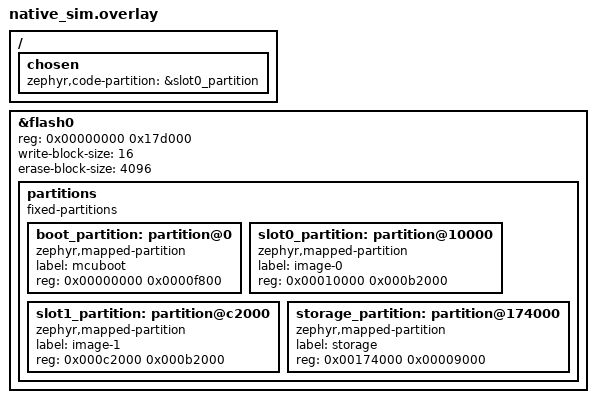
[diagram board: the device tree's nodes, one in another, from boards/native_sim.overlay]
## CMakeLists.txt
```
# Copyright (c) Meta Platforms, Inc. and affiliates.
#
# Licensed under the Apache License, Version 2.0 (the "License");
# you may not use this file except in compliance with the License.
# You may obtain a copy of the License at
#
#     http://www.apache.org/licenses/LICENSE-2.0
#
# Unless required by applicable law or agreed to in writing, software
# distributed under the License is distributed on an "AS IS" BASIS,
# WITHOUT WARRANTIES OR CONDITIONS OF ANY KIND, either express or implied.
# See the License for the specific language governing permissions and
# limitations under the License.

# The XIAO's firmware-update path on native_sim, for the Muse apps' mcumgr
# clients (README.md): Zephyr's MCUmgr (img_mgmt, os_mgmt, the BLE
# transport's reassembly) with the XIAO's settings, src/mg_ota.c as built
# for the board, and MCUboot's own loader (swap using move) run on the
# simulated RRAM at every start, behind a UDP "fake GATT" link.

cmake_minimum_required(VERSION 3.20.0)

find_package(Zephyr REQUIRED HINTS $ENV{ZEPHYR_BASE})
project(mg_smp_link)

set(MG_SRC ${CMAKE_CURRENT_SOURCE_DIR}/../../src)
set(MG_PROTOCOLS ${CMAKE_CURRENT_SOURCE_DIR}/../../../protocols)
set(MCUBOOT ${ZEPHYR_MCUBOOT_MODULE_DIR})

target_include_directories(app PRIVATE ${MG_SRC} src ${MG_PROTOCOLS}
  ${ZEPHYR_BASE}/subsys/mgmt/mcumgr/transport/include)
target_sources(app PRIVATE src/main.c src/link.c src/stubs.c src/boot_sim.c ${MG_SRC}/mg_ota.c)

# As on the XIAO: Zephyr's smp.c replaced by the board's copy
# (buffers and work queue allocated while SMP is in use), the image writer
# from the wrap in mg_smp_mem.c.
set(MG_SDK_SRC ${CMAKE_CURRENT_SOURCE_DIR}/../../src)
target_sources(app PRIVATE ${MG_SDK_SRC}/mg_smp_mem.c)
zephyr_link_libraries(-Wl,--wrap=img_mgmt_write_image_data)
get_target_property(mg_mcumgr_srcs mcumgr_transport SOURCES)
list(FILTER mg_mcumgr_srcs EXCLUDE REGEX "(^|/subsys/mgmt/mcumgr/transport/)src/smp\\.c$")
set_property(TARGET mcumgr_transport PROPERTY SOURCES ${mg_mcumgr_srcs})
target_sources(mcumgr_transport PRIVATE ${MG_SDK_SRC}/zephyr/smp.c)
target_link_libraries(app PRIVATE MCUBOOT_BOOTUTIL)
# As on the board (CMakeLists.txt): img_mgmt's state write goes through
# mg_ota.c's boot_set_next(). And an SMP reset ends the process with status
# 77 instead of re-executing it, so run.py can restart it (src/main.c).
zephyr_link_libraries(-Wl,--wrap=boot_set_next -Wl,--wrap=sys_arch_reboot)
# src/link.c feeds writes to the reassembly as smp_bt does (expected, then
# collect): through mg_ota.c's gap check, as on the board.
zephyr_link_libraries(-Wl,--wrap=smp_reassembly_expected -Wl,--wrap=smp_reassembly_collect)

# MCUboot's loader, configured like the XIAO's (mcuboot/mcuboot_config,
# found before MCUboot's own Zephyr config).
target_include_directories(app BEFORE PRIVATE ${CMAKE_CURRENT_SOURCE_DIR}/mcuboot)
target_include_directories(app PRIVATE
  ${MCUBOOT}/boot/bootutil/include ${MCUBOOT}/boot/bootutil/src
  ${MCUBOOT}/boot/zephyr/include ${MCUBOOT}/ext/tinycrypt/lib/include)
target_sources(app PRIVATE
  ${MCUBOOT}/boot/bootutil/src/loader.c
  ${MCUBOOT}/boot/bootutil/src/bootutil_loader.c
  ${MCUBOOT}/boot/bootutil/src/bootutil_misc.c
  ${MCUBOOT}/boot/bootutil/src/bootutil_area.c
  ${MCUBOOT}/boot/bootutil/src/swap_misc.c
  ${MCUBOOT}/boot/bootutil/src/swap_move.c
  ${MCUBOOT}/boot/bootutil/src/swap_scratch.c
  ${MCUBOOT}/boot/bootutil/src/image_validate.c
  ${MCUBOOT}/boot/bootutil/src/bootutil_img_hash.c
  ${MCUBOOT}/boot/bootutil/src/tlv.c
  ${MCUBOOT}/boot/bootutil/src/fault_injection_hardening.c
  ${MCUBOOT}/boot/zephyr/flash_map_extended.c
  ${MCUBOOT}/ext/tinycrypt/lib/source/sha256.c
  ${MCUBOOT}/ext/tinycrypt/lib/source/utils.c
)
# The release rule at run time (--release), for the update prompt rows.
target_compile_definitions(app PRIVATE MG_SMP_LINK_SIM)
```

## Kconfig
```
# Copyright (c) Meta Platforms, Inc. and affiliates.
#
# Licensed under the Apache License, Version 2.0 (the "License");
# you may not use this file except in compliance with the License.
# You may obtain a copy of the License at
#
#     http://www.apache.org/licenses/LICENSE-2.0
#
# Unless required by applicable law or agreed to in writing, software
# distributed under the License is distributed on an "AS IS" BASIS,
# WITHOUT WARRANTIES OR CONDITIONS OF ANY KIND, either express or implied.
# See the License for the specific language governing permissions and
# limitations under the License.

mainmenu "Muse Gadget SMP link harness"

# The few Muse Gadget options src/mg_ota.c reads. ../../Kconfig.mg is the
# source of truth (defaults and ranges copied from it; change both
# together): there they depend on MG_DFU, which needs BOOTLOADER_MCUBOOT,
# which native_sim doesn't build.
config MG_DFU_RESET_DISCONNECT_MS
	int "Delay from an SMP reset's answer to dropping the link (ms)"
	default 100
	range 20 400

config MG_SMP_SESSION_IDLE_MS
	int "Idle time after which SMP's work queue is freed (ms)"
	default 2000

config MG_SMP_RX_GAP_MS
	int "Gap after which a partly received SMP request is dropped (ms)"
	default 2000
	range 0 10000

config MG_SIM_LINK
	bool
	default y
	select MCUMGR_TRANSPORT_REASSEMBLY
	help
	  src/link.c reassembles SMP requests from ATT-sized writes, as the
	  BLE transport does (CONFIG_MCUMGR_TRANSPORT_BT_REASSEMBLY).

config MG_AUTOMATION
	bool "An automation build (the bench board's)"
	default y
	help
	  mg_ota.c's update window rule for a gadget that isn't set up applies
	  to release builds only, and this suite updates unset gadgets as CI
	  does.

config MG_BENCH_NO_CONFIRM
	bool "Never confirm a new image (revert test)"

module = MG
module-str = Muse Gadget
source "subsys/logging/Kconfig.template.log_config"

source "Kconfig.zephyr"
```

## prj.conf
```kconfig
# Copyright (c) Meta Platforms, Inc. and affiliates.
#
# Licensed under the Apache License, Version 2.0 (the "License");
# you may not use this file except in compliance with the License.
# You may obtain a copy of the License at
#
#     http://www.apache.org/licenses/LICENSE-2.0
#
# Unless required by applicable law or agreed to in writing, software
# distributed under the License is distributed on an "AS IS" BASIS,
# WITHOUT WARRANTIES OR CONDITIONS OF ANY KIND, either express or implied.
# See the License for the specific language governing permissions and
# limitations under the License.

# MCUmgr as the XIAO builds it (boards/xiao_nrf54l15_nrf54l15_cpuapp.conf;
# run.py checks the shared lines haven't drifted), minus Bluetooth: the
# link is UDP (src/link.c) feeding the same reassembly.
CONFIG_MCUMGR=y
CONFIG_NET_BUF=y
CONFIG_ZCBOR=y
CONFIG_CRC=y
CONFIG_FLASH=y
CONFIG_FLASH_MAP=y
CONFIG_STREAM_FLASH=y
CONFIG_IMG_MANAGER=y
CONFIG_MCUBOOT_IMG_MANAGER=y
CONFIG_MCUMGR_GRP_IMG=y
CONFIG_MCUMGR_GRP_IMG_STATUS_HOOKS=y
CONFIG_MCUMGR_GRP_IMG_UPLOAD_CHECK_HOOK=y
CONFIG_MCUMGR_GRP_OS=y
CONFIG_MCUMGR_GRP_OS_ECHO=y
CONFIG_MCUMGR_GRP_OS_INFO=y
CONFIG_MCUMGR_MGMT_NOTIFICATION_HOOKS=y
CONFIG_MCUMGR_TRANSPORT_NETBUF_SIZE=512
CONFIG_MCUMGR_TRANSPORT_NETBUF_COUNT=4
CONFIG_MCUMGR_GRP_OS_MCUMGR_PARAMS=y
CONFIG_IMG_BLOCK_BUF_SIZE=4096
CONFIG_IMG_ERASE_PROGRESSIVELY=y
CONFIG_MCUMGR_TRANSPORT_WORKQUEUE_STACK_SIZE=4096
CONFIG_MCUMGR_GRP_OS_RESET_MS=500
# What CONFIG_MG_DFU selects on the board.
CONFIG_MCUMGR_SMP_COMMAND_STATUS_HOOKS=y
CONFIG_MCUMGR_GRP_OS_RESET_HOOK=y
CONFIG_REBOOT=y
# The XIAO's MCUboot writes 16-byte RRAM words (CONFIG_MCUBOOT_BOOT_MAX_ALIGN
# from sysbuild); the loader here uses the same (mcuboot/mcuboot_config).
CONFIG_MCUBOOT_BOOT_MAX_ALIGN=16
# img_mgmt finds the running slot from the chosen code partition (slot0).
CONFIG_USE_DT_CODE_PARTITION=y
# RRAM: no erase before a write (as tests/unit's rram and slot1 builds).
CONFIG_FLASH_SIMULATOR=y
CONFIG_FLASH_SIMULATOR_EXPLICIT_ERASE=n
CONFIG_FLASH_SIMULATOR_UNALIGNED_READ=y
CONFIG_FLASH_SIMULATOR_DOUBLE_WRITES=y

# The UDP link: host sockets (native simulator offloaded sockets).
CONFIG_NETWORKING=y
CONFIG_NET_DRIVERS=y
CONFIG_NET_SOCKETS=y
CONFIG_NET_SOCKETS_OFFLOAD=y
CONFIG_NET_NATIVE_OFFLOADED_SOCKETS=y
CONFIG_NET_IPV6=n
CONFIG_NET_IPV4=y
CONFIG_ETH_NATIVE_TAP=n

CONFIG_MAIN_STACK_SIZE=8192
CONFIG_SYSTEM_WORKQUEUE_STACK_SIZE=4096
CONFIG_LOG=y
CONFIG_LOG_MODE_IMMEDIATE=y
CONFIG_MG_LOG_LEVEL_INF=y
CONFIG_IMG_MANAGER_LOG_LEVEL_INF=y
CONFIG_MCUMGR_GRP_IMG_LOG_LEVEL_INF=y

# SMP's memory from the C library's arena (all free RAM on the XIAO).
# Zephyr's own malloc (sys_heap over a fixed arena) as on the board, not the
# host's: native_sim links the host C library by default, whose malloc never
# runs out, and an arena that can't run out proves nothing about sharing it.
CONFIG_PICOLIBC=y
CONFIG_COMMON_LIBC_MALLOC=y
CONFIG_COMMON_LIBC_MALLOC_ARENA_SIZE=65536
# Asserts on: Zephyr's own checks on the buffers the smp.c copy makes.
CONFIG_ASSERT=y

# Room after the transport's user data for each request's source connection
# (src/zephyr/smp.c, change 3).
CONFIG_MCUMGR_TRANSPORT_NETBUF_USER_DATA_SIZE=16
```

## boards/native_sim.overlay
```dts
/*
 * Copyright (c) Meta Platforms, Inc. and affiliates.
 *
 * Licensed under the Apache License, Version 2.0 (the "License");
 * you may not use this file except in compliance with the License.
 * You may obtain a copy of the License at
 *
 *     http://www.apache.org/licenses/LICENSE-2.0
 *
 * Unless required by applicable law or agreed to in writing, software
 * distributed under the License is distributed on an "AS IS" BASIS,
 * WITHOUT WARRANTIES OR CONDITIONS OF ANY KIND, either express or implied.
 * See the License for the specific language governing permissions and
 * limitations under the License.
 */

/* The XIAO nRF54L15's RRAM map (nrf54l15_cpuapp_partition.dtsi): 1524 KB,
 * 16-byte words, MCUboot's slots at the board's offsets. */

/delete-node/ &boot_partition;
/delete-node/ &slot0_partition;
/delete-node/ &slot1_partition;
/delete-node/ &scratch_partition;
/delete-node/ &storage_partition;

&flash0 {
	reg = <0x00000000 0x17d000>;
	write-block-size = <16>;
	erase-block-size = <4096>;

	partitions {
		compatible = "fixed-partitions";
		#address-cells = <1>;
		#size-cells = <1>;

		boot_partition: partition@0 {
			compatible = "zephyr,mapped-partition";
			label = "mcuboot";
			reg = <0x00000000 0x0000f800>;
		};
		slot0_partition: partition@10000 {
			compatible = "zephyr,mapped-partition";
			label = "image-0";
			reg = <0x00010000 0x000b2000>;
		};
		slot1_partition: partition@c2000 {
			compatible = "zephyr,mapped-partition";
			label = "image-1";
			reg = <0x000c2000 0x000b2000>;
		};
		storage_partition: partition@174000 {
			compatible = "zephyr,mapped-partition";
			label = "storage";
			reg = <0x00174000 0x00009000>;
		};
	};
};

/ {
	chosen {
		zephyr,code-partition = &slot0_partition;
	};
};
```

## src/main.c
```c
/*
 * Copyright (c) Meta Platforms, Inc. and affiliates.
 *
 * Licensed under the Apache License, Version 2.0 (the "License");
 * you may not use this file except in compliance with the License.
 * You may obtain a copy of the License at
 *
 *     http://www.apache.org/licenses/LICENSE-2.0
 *
 * Unless required by applicable law or agreed to in writing, software
 * distributed under the License is distributed on an "AS IS" BASIS,
 * WITHOUT WARRANTIES OR CONDITIONS OF ANY KIND, either express or implied.
 * See the License for the specific language governing permissions and
 * limitations under the License.
 */

/*
 * Boot like the XIAO: MCUboot (boot_sim.c), then the app's update path
 * (mg_ota_init(), the SMP service on the link), healthy
 * --healthy-ms after it is up (CONFIG_MG_HEALTHY_AFTER_MS on the board,
 * 30 s). --crash-ms restarts before that, as a watchdog would (a test image
 * that never gets healthy). An SMP reset (or that crash) ends the process
 * with status 77; run.py starts it again, which is the next boot.
 */

#include <stdlib.h>

#include <zephyr/kernel.h>
#include <zephyr/sys/printk.h>

#include "cmdline.h"
#include "posix_board_if.h"
#include "soc.h"

#include "mg_ota.h"
#include "sim.h"
#include "mg_zephyr_version.h"

MG_ZEPHYR_WRAPS_CHECK(); /* __wrap_sys_arch_reboot */

#define EXIT_REBOOT 77

static uint32_t opt_port = 47000;
static uint32_t opt_healthy_ms = 30000;
static uint32_t opt_crash_ms;
static bool opt_never_healthy;
static bool opt_ready_at_healthy;
static uint32_t opt_hold_kb;
bool sim_healthy;
uint32_t sim_boot;

static void add_options(void)
{
	static struct args_struct_t opts[] = {
		{.option = "port", .name = "port", .type = 'u', .dest = &opt_port,
		 .descript = "UDP port of the fake GATT link (47000)"},
		{.option = "healthy-ms", .name = "ms", .type = 'u', .dest = &opt_healthy_ms,
		 .descript = "healthy this long after start (30000, the XIAO's)"},
		{.option = "crash-ms", .name = "ms", .type = 'u', .dest = &opt_crash_ms,
		 .descript = "restart this long after start, before healthy (a watchdog reset)"},
		{.is_switch = true, .option = "never-healthy", .type = 'b',
		 .dest = &opt_never_healthy, .descript = "never reach healthy"},
		{.is_switch = true, .option = "safe", .type = 'b', .dest = &sim_safe_mode,
		 .descript = "run in SAFE mode (from failed boots)"},
		{.is_switch = true, .option = "safe-button", .type = 'b', .dest = &sim_safe_button,
		 .descript = "with --safe: SAFE mode asked with the button"},
		{.is_switch = true, .option = "set-up", .type = 'b', .dest = &sim_set_up,
		 .descript = "set up (a proof key stored; on --release the update gate asks the "
			     "same either way)"},
		{.is_switch = true, .option = "release", .type = 'b', .dest = &sim_release,
		 .descript = "a release build's update rule (unproven writes ask for the press)"},
		{.is_switch = true, .option = "proven", .type = 'b', .dest = &sim_proven,
		 .descript = "the client passed the token proof"},
		{.option = "boot", .name = "n", .type = 'u', .dest = &sim_boot,
		 .descript = "this boot's number (run.py counts them)"},
		{.option = "hold-kb", .name = "kb", .type = 'u', .dest = &opt_hold_kb,
		 .descript = "take this much of the malloc arena at start and keep it (the "
			     "device session's block, which shares the arena with SMP)"},
		{.is_switch = true, .option = "ready-at-healthy", .type = 'b',
		 .dest = &opt_ready_at_healthy,
		 .descript = "answer connects with ready only once healthy"},
		ARG_TABLE_ENDMARKER,
	};

	native_add_command_line_opts(opts);
}

NATIVE_TASK(add_options, PRE_BOOT_1, 10);

/* sys_reboot() (the SMP reset, a crash) ends here: hand back to run.py. */
void __wrap_sys_arch_reboot(int type)
{
	printk("SIM: reboot (%d)\n", type);
	posix_exit(EXIT_REBOOT);
}

static void healthy_fn(struct k_work *w)
{
	ARG_UNUSED(w);
	printk("SIM: boot healthy\n");
	sim_healthy = true;
	if (opt_ready_at_healthy) {
		link_set_ready(true);
	}
	mg_ota_healthy();
}

static K_WORK_DELAYABLE_DEFINE(healthy_work, healthy_fn);

static void crash_fn(struct k_work *w)
{
	ARG_UNUSED(w);
	printk("SIM: crash before healthy (watchdog)\n");
	posix_exit(EXIT_REBOOT);
}

static K_WORK_DELAYABLE_DEFINE(crash_work, crash_fn);

/* The native simulator sets every 'u' option it wasn't given to UINT32_MAX. */
static void option_defaults(void)
{
	if (opt_port == UINT32_MAX) {
		opt_port = 47000;
	}
	if (opt_healthy_ms == UINT32_MAX) {
		opt_healthy_ms = 30000;
	}
	if (opt_crash_ms == UINT32_MAX) {
		opt_crash_ms = 0;
	}
	if (sim_boot == UINT32_MAX) {
		sim_boot = 0;
	}
	if (opt_hold_kb == UINT32_MAX) {
		opt_hold_kb = 0;
	}
}

int main(void)
{
	option_defaults();
	sim_proven_at_connect = sim_proven;
	if (boot_sim_run() != 0) {
		posix_exit(2);
	}
	sim_app_wq_start();
	if (opt_hold_kb) {
		/* As the device session's block (from a hello to the connection's
		 * end): taken before SMP's, from the same arena, never given back. */
		void *held = malloc(opt_hold_kb * 1024U);

		printk("SIM: holding %u KB of the malloc arena%s\n", opt_hold_kb,
		       held ? "" : ": FAILED");
		if (held == NULL) {
			posix_exit(4);
		}
	}
	mg_ota_init();
	if (link_start((uint16_t)opt_port) != 0) {
		posix_exit(3);
	}
	link_set_ready(!opt_ready_at_healthy);
	printk("SIM: up (healthy in %u ms%s%s)\n", opt_healthy_ms,
	       opt_never_healthy ? ", never" : "", sim_safe_mode ? ", SAFE mode" : "");
	if (opt_crash_ms) {
		k_work_reschedule(&crash_work, K_MSEC(opt_crash_ms));
	}
	if (!opt_never_healthy && !opt_crash_ms) {
		k_work_reschedule(&healthy_work, K_MSEC(opt_healthy_ms));
	}
	return 0;
}
```

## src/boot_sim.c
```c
/*
 * Copyright (c) Meta Platforms, Inc. and affiliates.
 *
 * Licensed under the Apache License, Version 2.0 (the "License");
 * you may not use this file except in compliance with the License.
 * You may obtain a copy of the License at
 *
 *     http://www.apache.org/licenses/LICENSE-2.0
 *
 * Unless required by applicable law or agreed to in writing, software
 * distributed under the License is distributed on an "AS IS" BASIS,
 * WITHOUT WARRANTIES OR CONDITIONS OF ANY KIND, either express or implied.
 * See the License for the specific language governing permissions and
 * limitations under the License.
 */

/*
 * The reset path: MCUboot's own loader (bootutil, configured in
 * ../mcuboot/mcuboot_config) runs on the simulated flash before the app
 * starts, so a test, a confirm, a revert and a refused image go through
 * MCUboot's real swap-using-move code. What the app reports comes from the
 * flash, as on the board.
 */

#include <zephyr/logging/log.h>
#include <zephyr/sys/printk.h>

#include <bootutil/bootutil.h>
#include <bootutil/fault_injection_hardening.h>
#include <bootutil/image.h>

#include "sim.h"

LOG_MODULE_REGISTER(mcuboot, LOG_LEVEL_INF);

int boot_sim_run(void)
{
	struct boot_rsp rsp;
	FIH_DECLARE(fih_rc, FIH_FAILURE);

	FIH_CALL(boot_go, fih_rc, &rsp);
	if (FIH_NOT_EQ(fih_rc, FIH_SUCCESS)) {
		printk("SIM: mcuboot: no bootable image\n");
		return -1;
	}
	printk("SIM: mcuboot: booting %u.%u.%u+%u\n", rsp.br_hdr->ih_ver.iv_major,
	       rsp.br_hdr->ih_ver.iv_minor, rsp.br_hdr->ih_ver.iv_revision,
	       rsp.br_hdr->ih_ver.iv_build_num);
	return 0;
}
```

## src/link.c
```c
/*
 * Copyright (c) Meta Platforms, Inc. and affiliates.
 *
 * Licensed under the Apache License, Version 2.0 (the "License");
 * you may not use this file except in compliance with the License.
 * You may obtain a copy of the License at
 *
 *     http://www.apache.org/licenses/LICENSE-2.0
 *
 * Unless required by applicable law or agreed to in writing, software
 * distributed under the License is distributed on an "AS IS" BASIS,
 * WITHOUT WARRANTIES OR CONDITIONS OF ANY KIND, either express or implied.
 * See the License for the specific language governing permissions and
 * limitations under the License.
 */

/*
 * The "fake GATT" link (the one
 * esp32/components/muse_gadget_ble/smp/conformance/smplink.py speaks): UDP
 * datagrams of one type byte and a value. Data
 * from the client is one ATT write without response (at most MTU - 3
 * bytes); data to it is one notification. The SMP side copies smp_bt.c:
 * every write goes through Zephyr's SMP reassembly into the board's
 * buffers, a response is cut into MTU - 3 notifications, and a response to
 * a request from an earlier connection is dropped. A disconnect drops a
 * partly received request, as smp_bt's CCC cleanup does for a central that
 * subscribed; a disconnect whose value byte is 1 is a central that never
 * subscribed, and keeps it, as smp_bt does (GATT's cleanup skips a CCC that
 * was never enabled), so the board's own reassembly wraps (src/mg_ota.c)
 * must drop it before the next connection's writes complete it.
 */

#include <errno.h>
#include <string.h>

#include <stdio.h>

#include <zephyr/dfu/mcuboot.h>
#include <zephyr/kernel.h>
#include <zephyr/mgmt/mcumgr/mgmt/mgmt_defines.h>
#include <zephyr/storage/flash_map.h>
#include <zephyr/mgmt/mcumgr/smp/smp.h>
#include <zephyr/mgmt/mcumgr/transport/smp.h>
#include <zephyr/net/socket.h>
#include <zephyr/sys/atomic.h>
#include <zephyr/sys/printk.h>

#include <mgmt/mcumgr/transport/smp_reassembly.h>

#include "mg_ota.h"
#include "sim.h"

/* The largest attribute value ATT allows (Core spec Vol 3 Part F 3.2.9). */
#define ATT_MAX_VALUE 512U

enum {
	T_DATA = 0x00,
	T_CONNECT = 0x01,
	T_DISCONNECT = 0x02,
	T_READY = 0x04,
	T_DROP_NEXT = 0x05,
	T_STATUS = 0x07,
	T_AUTH = 0x09, /* this connection proven (1) or not (0): the update gate */
	/* This app's own, outside the link's shared range: a setup committed (an
	 * ownership change), as mg_setup_store_commit_device_key() reports it. */
	T_SETUP_COMMITTED = 0x40,
	T_PRESS = 0x41, /* a real press of the talk button (the update prompt) */
	T_INJECTED = 0x42, /* an injected press (a console word): never a confirm on release */
	/* Forget (the token proof's clear, the sealed clear, the reset hold):
	 * the link's proof ends, then the store is erased (mg_setup_factory_reset()). */
	T_FORGET = 0x43,
};

/* src/mg_ota.c: the setup store erased (mg_setup_store_erase() reports it). */
void mg_setup_store_erased(void);

#define MAX_DGRAM 600 /* MTU 517 + the type byte, with room */

struct link_ud {
	uint32_t id; /* the connection the request came on */
};
BUILD_ASSERT(sizeof(struct link_ud) <= CONFIG_MCUMGR_TRANSPORT_NETBUF_USER_DATA_SIZE);

static int sock = -1;
static struct net_sockaddr_in peer;
static bool have_peer;
static uint16_t att_mtu = 23;
static atomic_t conn_id;    /* 0: no client */
static uint32_t next_id = 1;
static bool gatt_ready;
static bool held;
static int drop_next;
static bool kept_partial; /* left by a central that never subscribed */
static struct smp_transport smpt;
static K_MUTEX_DEFINE(tx_lock);

static void send_dgram(uint8_t type, const uint8_t *v, size_t n)
{
	uint8_t d[MAX_DGRAM];

	if (!have_peer || sock < 0 || n + 1 > sizeof(d)) {
		return;
	}
	d[0] = type;
	if (n) {
		memcpy(&d[1], v, n);
	}
	(void)zsock_sendto(sock, d, n + 1, 0, (struct net_sockaddr *)&peer, sizeof(peer));
}

static uint16_t link_get_mtu(const struct net_buf *nb)
{
	ARG_UNUSED(nb);
	return atomic_get(&conn_id) ? att_mtu - 3 : 0;
}

static int link_tx(struct net_buf *nb)
{
	const struct link_ud *ud = net_buf_user_data(nb);
	int rc = MGMT_ERR_EOK;
	uint32_t id = (uint32_t)atomic_get(&conn_id);

	if (id == 0 || ud->id != id) {
		/* The client that asked is gone (smp_bt drops these too). */
		rc = MGMT_ERR_ENOENT;
	} else {
		uint16_t chunk = att_mtu - 3;

		k_mutex_lock(&tx_lock, K_FOREVER);
		for (uint16_t off = 0; off < nb->len; off += chunk) {
			send_dgram(T_DATA, nb->data + off, MIN(chunk, nb->len - off));
		}
		k_mutex_unlock(&tx_lock);
	}
	smp_packet_free(nb);
	return rc;
}

static int link_ud_copy(struct net_buf *dst, const struct net_buf *src)
{
	memcpy(net_buf_user_data(dst), net_buf_user_data(src), sizeof(struct link_ud));
	return MGMT_ERR_EOK;
}

static void link_ud_free(void *ud)
{
	ARG_UNUSED(ud);
}

static void drop_partial(void)
{
	if (smp_reassembly_expected(&smpt) >= 0) {
		(void)smp_reassembly_drop(&smpt);
	}
}

static void on_data(const uint8_t *v, size_t n)
{
	uint32_t id = (uint32_t)atomic_get(&conn_id);

	if (id == 0 || n == 0) {
		return;
	}
	kept_partial = false; /* the board's wraps decide from here */
	if (drop_next > 0) {
		drop_next--;
		printk("SIM: link: dropped a write (%u B) as asked\n", (unsigned int)n);
		return;
	}
	if (n > att_mtu - 3U || n > ATT_MAX_VALUE) {
		/* Android refuses a write over 512 B whatever the MTU (and ATT
		 * caps an attribute value there): count it as a failure. */
		printk("SIM: link: write of %u B is over MTU - 3 (%u) or %u: refused\n",
		       (unsigned int)n, att_mtu - 3U, ATT_MAX_VALUE);
		return;
	}
	bool started = smp_reassembly_expected(&smpt) >= 0;
	int ret = smp_reassembly_collect(&smpt, v, (uint16_t)n);

	if (ret < 0) {
		printk("SIM: link: reassembly refused a write (%d): request dropped\n", ret);
		drop_partial();
		return;
	}
	if (!started) {
		struct link_ud *ud = smp_reassembly_get_ud(&smpt);

		if (ud) {
			ud->id = id;
		}
	}
	if (ret == 0) {
		(void)smp_reassembly_complete(&smpt, false);
	}
}

static bool slot_version(uint8_t area, char *out, size_t len)
{
	struct mcuboot_img_header h;

	if (boot_read_bank_header(area, &h, sizeof(h)) != 0) {
		snprintf(out, len, "none");
		return false;
	}
	snprintf(out, len, "%u.%u.%u+%u", h.h.v1.sem_ver.major, h.h.v1.sem_ver.minor,
		 h.h.v1.sem_ver.revision, h.h.v1.sem_ver.build_num);
	return true;
}

/* 0x07: what the running gadget says about itself, for checks. */
static void send_status(void)
{
	static const char *const swaps[] = {"?", "none", "test", "perm", "revert", "fail"};
	char running[24], staged[24], j[256];
	int swap = mcuboot_swap_type();
	bool has_staged = slot_version(FIXED_PARTITION_ID(slot1_partition), staged, sizeof(staged));

	(void)slot_version(FIXED_PARTITION_ID(slot0_partition), running, sizeof(running));
	int n = snprintf(j, sizeof(j),
			 "{\"running\":\"%s\",\"confirmed\":%s,\"swap\":\"%s\",\"pending\":%s,"
			 "\"staged\":%s,\"staged_version\":\"%s\",\"healthy\":%s,\"boot\":%u,"
			 "\"safe\":%s,\"smp_blocks\":%d}",
			 running, boot_is_img_confirmed() ? "true" : "false",
			 swap >= 0 && swap < (int)ARRAY_SIZE(swaps) ? swaps[swap] : "?",
			 swap != BOOT_SWAP_TYPE_NONE ? "true" : "false", has_staged ? "true" : "false",
			 staged, sim_healthy ? "true" : "false", sim_boot, sim_safe_mode ? "true" : "false",
			 mg_smp_mem_blocks());

	send_dgram(T_STATUS, (const uint8_t *)j, (size_t)MIN(n, (int)sizeof(j) - 1));
}

static void rx_fn(void *a, void *b, void *c)
{
	uint8_t d[MAX_DGRAM];

	ARG_UNUSED(a);
	ARG_UNUSED(b);
	ARG_UNUSED(c);
	for (;;) {
		struct net_sockaddr_in from;
		net_socklen_t fl = sizeof(from);
		ssize_t n = zsock_recvfrom(sock, d, sizeof(d), 0, (struct net_sockaddr *)&from, &fl);

		if (n < 1) {
			k_sleep(K_MSEC(10));
			continue;
		}
		if (have_peer && (from.sin_port != peer.sin_port ||
				  from.sin_addr.s_addr != peer.sin_addr.s_addr) &&
		    d[0] != T_CONNECT) {
			continue; /* only the client that connected speaks for the link */
		}
		peer = from;
		have_peer = true;
		switch (d[0]) {
		case T_DATA:
			on_data(&d[1], (size_t)n - 1);
			break;
		case T_CONNECT:
			if (held) {
				break; /* restarting: no new link */
			}
			att_mtu = n >= 3 ? (uint16_t)(d[1] | (d[2] << 8)) : 23;
			att_mtu = CLAMP(att_mtu, 23, MAX_DGRAM - 1);
			if (!kept_partial) {
				drop_partial();
			}
			drop_next = 0;
			atomic_set(&conn_id, (atomic_val_t)next_id++);
			sim_proven = sim_proven_at_connect; /* --proven: every connection */
			printk("SIM: link: connected (ATT MTU %u)\n", att_mtu);
			/* A working link: as the gadget's own MTU exchange answered
			 * (mg_ble.c), so an updated image may keep itself. */
			mg_ota_link_proven();
			if (gatt_ready) {
				send_dgram(T_READY, NULL, 0);
			}
			break;
		case T_DISCONNECT:
			if (atomic_get(&conn_id)) {
				printk("SIM: link: the client disconnected\n");
			}
			atomic_set(&conn_id, 0);
			sim_proven = false;
			/* smp_bt asks nothing at such a disconnect: neither does this. */
			kept_partial = n >= 2 && d[1] == 1;
			if (kept_partial) {
				printk("SIM: link: the central never subscribed: a partial request stays\n");
			} else {
				drop_partial();
			}
			break;
		case T_AUTH:
			/* As a token proof on this connection (or its lapse: a new
			 * challenge). */
			sim_proven = n >= 2 && d[1] != 0;
			printk("SIM: link: this connection %s\n", sim_proven ? "proven" : "not proven");
			break;
		case T_DROP_NEXT:
			drop_next = n >= 2 ? d[1] : 1;
			break;
		case T_SETUP_COMMITTED:
			printk("SIM: link: a setup committed\n");
			mg_ota_setup_committed();
			break;
		case T_FORGET:
			printk("SIM: link: Forget\n");
			sim_proven = false;
			mg_setup_store_erased();
			break;
		case T_PRESS:
			printk("SIM: link: a press: %s\n",
			       mg_ota_prompt_take(true, false) ? "confirmed the update" : "no prompt");
			break;
		case T_INJECTED:
			printk("SIM: link: an injected press: %s\n",
			       mg_ota_prompt_take(false, !sim_release) ? "confirmed the update"
								       : "not a confirm");
			break;
		case T_STATUS:
			send_status();
			break;
		default:
			break;
		}
	}
}

static K_THREAD_STACK_DEFINE(link_rx_stack, 8192);
static struct k_thread rx_thread;

int link_start(uint16_t port)
{
	struct net_sockaddr_in addr = {
		.sin_family = NET_AF_INET,
		.sin_port = net_htons(port),
	};

	smpt.functions.output = link_tx;
	smpt.functions.get_mtu = link_get_mtu;
	smpt.functions.ud_copy = link_ud_copy;
	smpt.functions.ud_free = link_ud_free;
	if (smp_transport_init(&smpt) != 0) {
		return -EIO;
	}
	sock = zsock_socket(NET_AF_INET, NET_SOCK_DGRAM, NET_IPPROTO_UDP);
	if (sock < 0) {
		return -errno;
	}
	/* The fixture's port on the host's loopback only: its test hooks (proof
	 * state, a setup's commit) come from the local relay or client, never
	 * another host. */
	(void)zsock_inet_pton(NET_AF_INET, "127.0.0.1", &addr.sin_addr);
	if (zsock_bind(sock, (struct net_sockaddr *)&addr, sizeof(addr)) < 0) {
		printk("SIM: link: can't bind UDP port %u (%d)\n", port, errno);
		return -errno;
	}
	k_thread_create(&rx_thread, link_rx_stack, K_THREAD_STACK_SIZEOF(link_rx_stack), rx_fn, NULL, NULL,
			NULL, K_PRIO_PREEMPT(4), 0, K_NO_WAIT);
	k_thread_name_set(&rx_thread, "link_rx");
	printk("SIM: link: listening on UDP port %u\n", port);
	return 0;
}

void link_set_ready(bool ready)
{
	gatt_ready = ready;
	if (ready && atomic_get(&conn_id)) {
		send_dgram(T_READY, NULL, 0);
	}
}

void link_hold_for_reset(void)
{
	held = true;
	if (atomic_get(&conn_id)) {
		printk("SIM: link: dropping the client before the reset\n");
		send_dgram(T_DISCONNECT, NULL, 0);
	}
	atomic_set(&conn_id, 0);
	sim_proven = false;
	kept_partial = false;
	drop_partial();
}

uint32_t mg_transport_conn_gen(void)
{
	return (uint32_t)atomic_get(&conn_id);
}

void mg_transport_rx_request(void)
{
}

void mg_transport_peer_wrote(void)
{
}

bool mg_transport_link_up(void)
{
	return atomic_get(&conn_id) != 0;
}

bool mg_transport_link_seen_take(unsigned int who)
{
	ARG_UNUSED(who);
	return false;
}
```

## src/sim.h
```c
/*
 * Copyright (c) Meta Platforms, Inc. and affiliates.
 *
 * Licensed under the Apache License, Version 2.0 (the "License");
 * you may not use this file except in compliance with the License.
 * You may obtain a copy of the License at
 *
 *     http://www.apache.org/licenses/LICENSE-2.0
 *
 * Unless required by applicable law or agreed to in writing, software
 * distributed under the License is distributed on an "AS IS" BASIS,
 * WITHOUT WARRANTIES OR CONDITIONS OF ANY KIND, either express or implied.
 * See the License for the specific language governing permissions and
 * limitations under the License.
 */

#ifndef MG_SIM_H_
#define MG_SIM_H_

#include <stdbool.h>
#include <stdint.h>

/* boot_sim.c: MCUboot's boot_go() on the simulated flash, as at a reset.
 * 0, or <0 when no image can boot (the process then exits). */
int boot_sim_run(void);

/* link.c: the UDP "fake GATT" link (README.md, The link). */
int link_start(uint16_t port);
/* GATT is up: answer connects with ready (now, or the next one). */
void link_set_ready(bool ready);
/* The SMP reset is coming: drop the client (0x02) and take no connect. */
void link_hold_for_reset(void);

/* stubs.c, main.c */
void sim_app_wq_start(void);
extern bool sim_safe_mode;
extern bool sim_safe_button; /* SAFE mode asked with the button */
extern bool sim_set_up; /* a proof key stored */
extern bool sim_proven; /* this connection passed the token proof */
extern bool sim_release; /* --release: a release build's update rule */
extern bool sim_proven_at_connect; /* --proven: each connection starts proven */
extern bool sim_healthy;
extern uint32_t sim_boot; /* this boot's number since run.py started (--boot) */

/* ../../src/mg_smp_mem.c: memory blocks SMP holds right now (0 when idle). */
int mg_smp_mem_blocks(void);

#endif
```

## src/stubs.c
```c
/*
 * Copyright (c) Meta Platforms, Inc. and affiliates.
 *
 * Licensed under the Apache License, Version 2.0 (the "License");
 * you may not use this file except in compliance with the License.
 * You may obtain a copy of the License at
 *
 *     http://www.apache.org/licenses/LICENSE-2.0
 *
 * Unless required by applicable law or agreed to in writing, software
 * distributed under the License is distributed on an "AS IS" BASIS,
 * WITHOUT WARRANTIES OR CONDITIONS OF ANY KIND, either express or implied.
 * See the License for the specific language governing permissions and
 * limitations under the License.
 */

/* What src/mg_ota.c calls outside itself, for the harness. */

#include <zephyr/kernel.h>

#include "mg_app.h"
#include "mg_audio.h"
#include "mg_boot.h"
#include "mg_connparam.h"
#include "mg_transport.h"
#include "sim.h"

bool sim_safe_mode;
bool sim_release; /* --release: mg_ota.c's release rule (MG_SMP_LINK_SIM) */

static K_THREAD_STACK_DEFINE(app_stack, 4096);
static struct k_work_q app_wq;

void sim_app_wq_start(void)
{
	k_work_queue_start(&app_wq, app_stack, K_THREAD_STACK_SIZEOF(app_stack),
			   K_PRIO_PREEMPT(5), NULL);
	k_thread_name_set(&app_wq.thread, "mg_app");
}

struct k_work_q *mg_app_wq(void)
{
	return &app_wq;
}

const char *mg_app_version(void)
{
	return "smp_link";
}

bool mg_health_safe(void)
{
	return sim_safe_mode;
}

bool sim_safe_button;

bool mg_health_safe_by_button(void)
{
	return sim_safe_mode && sim_safe_button;
}

/* No watchdog here: the last feed before an SMP reset (mg_ota.c) does nothing. */
void mg_health_feed_now(void)
{
}

void mg_health_peer_bound_clear(const char *why)
{
	ARG_UNUSED(why);
}

void mg_button_flush_injected(void)
{
}

void mg_led_set(uint32_t flag, bool on)
{
	ARG_UNUSED(flag);
	ARG_UNUSED(on);
}

/* Set up (a proof key stored; the update gate no longer reads it) and this
 * connection proven (the update gate's input). */
bool sim_set_up;
bool sim_proven;
bool sim_proven_at_connect;

bool mg_setup_store_complete(void)
{
	return sim_set_up;
}

bool mg_token_proof_matched(void)
{
	return sim_proven;
}

void mg_audio_stop(void)
{
}

void mg_connparam_busy(enum mg_xfer what)
{
	ARG_UNUSED(what);
}

void mg_ble_hold_for_reset(void)
{
	link_hold_for_reset();
}
```
